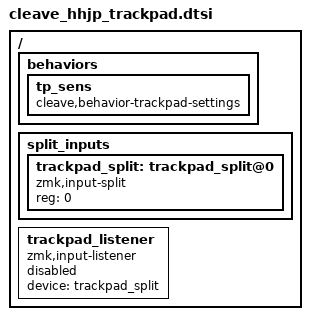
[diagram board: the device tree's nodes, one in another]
/* SPDX-License-Identifier: MIT */

/ {
	behaviors {
		tp_sens: tp_sens {
			compatible = "cleave,behavior-trackpad-settings";
			#binding-cells = <1>;
		};
	};
	split_inputs {
		#address-cells = <1>;
		#size-cells = <0>;

		trackpad_split: trackpad_split@0 {
			compatible = "zmk,input-split";
			reg = <0>;
		};
	};

	trackpad_listener: trackpad_listener {
		compatible = "zmk,input-listener";
		status = "disabled";
		device = <&trackpad_split>;
	};
};
